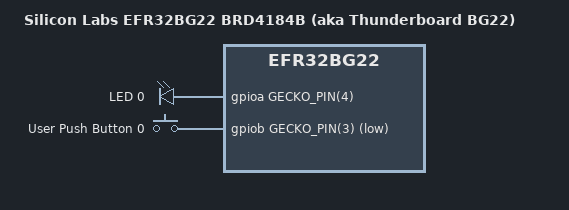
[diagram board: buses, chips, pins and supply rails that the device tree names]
/*
 * Copyright (c) 2021 Sateesh Kotapati
 *
 * SPDX-License-Identifier: Apache-2.0
 */
/dts-v1/;
#include <silabs/efr32bg22c224f512im40.dtsi>
#include <silabs/efr32bg22-pinctrl.dtsi>
#include "efr32bg22_brd.dtsi"

/ {
	model = "Silicon Labs EFR32BG22 BRD4184B (aka Thunderboard BG22)";
	compatible = "silabs,efr32bg22_brd4184a", "silabs,efr32bg22";

	leds {
		compatible = "gpio-leds";
		led0: led_0 {
			gpios = <&gpioa GECKO_PIN(4) GPIO_ACTIVE_HIGH>;
			label = "LED 0";
		};
	};

	buttons {
		compatible = "gpio-keys";
		button0: button_0 {
			gpios = <&gpiob GECKO_PIN(3) GPIO_ACTIVE_LOW>;
			label = "User Push Button 0";
		};
	};
};
